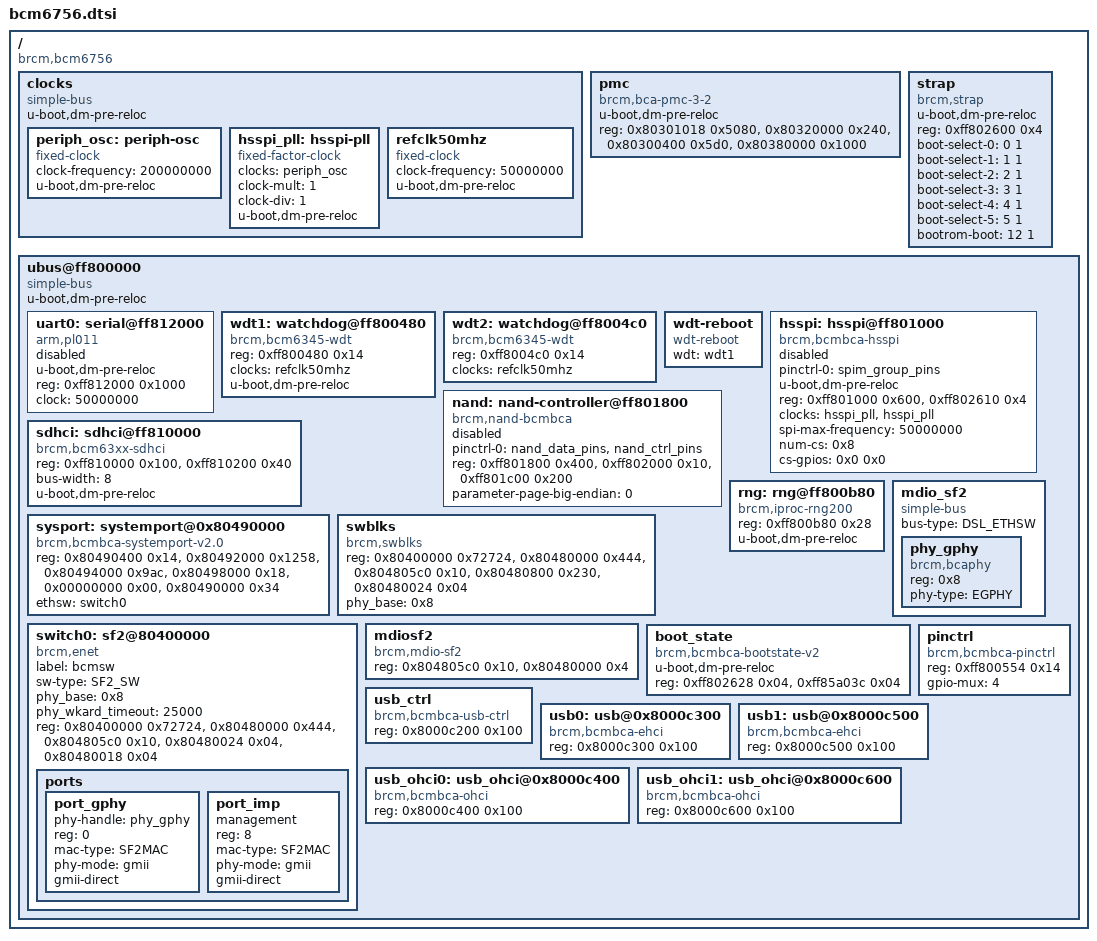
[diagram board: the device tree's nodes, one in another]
// SPDX-License-Identifier: GPL-2.0+
/*
 * Copyright 2021 Broadcom Ltd.
 */

#include "skeleton.dtsi"

/ {
	compatible = "brcm,bcm6756";
	#address-cells = <0x1>;
	#size-cells = <0x1>;

	clocks {
		compatible = "simple-bus";
		#address-cells = <1>;
		#size-cells = <1>;
		ranges;
		u-boot,dm-pre-reloc;

		periph_osc: periph-osc {
			compatible = "fixed-clock";
			#clock-cells = <0>;
			clock-frequency = <200000000>;
			u-boot,dm-pre-reloc;
		};

		hsspi_pll: hsspi-pll {
			compatible = "fixed-factor-clock";
			#clock-cells = <0>;
			clocks = <&periph_osc>;
			clock-mult = <1>;
			clock-div = <1>;
			u-boot,dm-pre-reloc;
		};

		refclk50mhz: refclk50mhz {
			compatible = "fixed-clock";
			#clock-cells = <0>;
			clock-frequency = <50000000>;
			u-boot,dm-pre-reloc;
		};
	};

	pmc {
		u-boot,dm-pre-reloc;
		compatible = "brcm,bca-pmc-3-2";
		reg-names = "pmc", "procmon", "maestro","dtcm"; 
 		reg = <0x80301018 0x5080>,
 		      <0x80320000 0x240>,
 		      <0x80300400 0x5d0>,
 		      <0x80380000 0x1000>;
	};

	strap: strap {
		u-boot,dm-pre-reloc;	
		compatible = "brcm,strap";
		reg = <0xff802600 0x4>;
		boot-select-0=<0 1>;
		boot-select-1=<1 1>;
		boot-select-2=<2 1>;
		boot-select-3=<3 1>;
		boot-select-4=<4 1>;
		boot-select-5=<5 1>;
		bootrom-boot=<12 1>;
	};

	ubus@ff800000 {
		compatible = "simple-bus";
		#address-cells = <0x1>;
		#size-cells = <0x1>;
		u-boot,dm-pre-reloc;

		uart0: serial@ff812000 {	
			u-boot,dm-pre-reloc;
			compatible = "arm,pl011", "arm,primecell";
			reg = <0xff812000 0x1000>;
			clock = <50000000>;
			status = "disabled";
		};

		wdt1: watchdog@ff800480 {
			compatible = "brcm,bcm6345-wdt";
			reg = <0xff800480 0x14>;
			clocks = <&refclk50mhz>;
			u-boot,dm-pre-reloc;
		};

		wdt2: watchdog@ff8004c0 {
			compatible = "brcm,bcm6345-wdt";
			reg = <0xff8004c0 0x14>;
			clocks = <&refclk50mhz>;
		};

		wdt-reboot {
			compatible = "wdt-reboot";
			wdt = <&wdt1>;
		};

		hsspi: hsspi@ff801000 {
			pinctrl-0 = <&spim_group_pins>;
			pinctrl-names = "default";
			#address-cells = <0x1>;
			#size-cells = <0x0>;
			u-boot,dm-pre-reloc;
			compatible = "brcm,bcmbca-hsspi";
			reg-names = "hsspi", "spim-ctrl";
			reg = <0xff801000 0x600>, <0xff802610 0x4>;
			clocks = <&hsspi_pll>, <&hsspi_pll>;
			clock-names = "hsspi", "pll";
			spi-max-frequency = <50000000>;
			num-cs = <0x8>;
			cs-gpios = <0x0 0x0>;
			status = "disabled";
		};

		nand: nand-controller@ff801800 {
			pinctrl-0 = <&nand_data_pins &nand_ctrl_pins>;
			pinctrl-names = "default";	
			compatible = "brcm,nand-bcmbca",
				     "brcm,brcmnand-v7.1",
				     "brcm,brcmnand";
			reg-names = "nand", "nand-int-base", "nand-cache";
			reg = <0xff801800 0x400>,
			      <0xff802000 0x10>,
			      <0xff801c00 0x200>;
			parameter-page-big-endian = <0>;
			status = "disabled";
		};

		sdhci: sdhci@ff810000 {
			compatible = "brcm,bcm63xx-sdhci",
			             "brcm,sdhci-brcmbca";
			reg-names = "sdhci-base", "sdhci-boot";
			reg = <0xff810000 0x100>,
			      <0xff810200 0x40>;
			bus-width = <8>;
			u-boot,dm-pre-reloc;
		};

		rng: rng@ff800b80 {
			compatible = "brcm,iproc-rng200";
			reg = <0xff800b80 0x28>;
			u-boot,dm-pre-reloc;
		};
		
		sysport: systemport@0x80490000 {
			compatible = "brcm,bcmbca-systemport-v2.0";
			reg-names = "systemport-rbuf-base", "systemport-rdma-base",
					"systemport-tdma-base",
					"systemport-gib-base",
					"systemport-umac-base",
					"systemport-topctrl-base";
			reg =		<0x80490400 0x14>,
					<0x80492000 0x1258>,
					<0x80494000 0x9ac>,
					<0x80498000 0x18>,
					<0x00000000 0x00>,  
					<0x80490000 0x34>;
			ethsw = <&switch0>;
		};

    	swblks {
    		compatible = "brcm,swblks";
    		reg-names =	"switchcore-base",
    				"switchreg-base",
    				"switchmdio-base",
    				"switchacb-base",
    				"sphy-ctrl";

    		reg	= <0x80400000 0x72724>,
    			<0x80480000 0x444>,
    			<0x804805c0 0x10>,
    			<0x80480800 0x230>,
    			<0x80480024 0x04>;
    		phy_base = <0x8>;
    	};

		mdio_sf2: mdio_sf2 {
			compatible = "simple-bus";
			bus-type = "DSL_ETHSW";

			#address-cells = <1>;
			#size-cells = <0>;

			phy_gphy:phy_gphy {
				compatible = "brcm,bcaphy";
				reg = <0x8>;
				phy-type = "EGPHY";
			};
		};

		switch0:sf2@80400000 {
			compatible = "brcm,enet", "brcm,bcmbca-sf2";
			label = "bcmsw";
			sw-type = "SF2_SW";

			phy_base = <0x8>;
			phy_wkard_timeout = <25000>;
			reg-names = "switchcore-base",
						"switchreg-base",
						"switchmdio-base",
						"sphy-ctrl",
						"phy-test-ctrl";

			reg = <0x80400000 0x72724>,
				<0x80480000 0x444>,
				<0x804805c0 0x10>,
				<0x80480024 0x04>,
				<0x80480018 0x04>;

			ports {
				#address-cells = <1>;
				#size-cells = <0>;

				port_gphy {
					phy-handle = <&phy_gphy>;
					reg = <0>;
					mac-type = "SF2MAC";
					phy-mode = "gmii";
					gmii-direct;
				};
				port_imp {
					management;
					reg = <8>;
					mac-type = "SF2MAC";
					phy-mode = "gmii";
					gmii-direct;
				};
			};		
		};

		mdiosf2 {
			compatible = "brcm,mdio-sf2";
			reg = <0x804805c0 0x10>,
				  <0x80480000 0x4>;
		};

		boot_state {
			u-boot,dm-pre-reloc;
			compatible = "brcm,bcmbca-bootstate-v2";
			reg-names = "reset_reason", "reset_status";
			reg = <0xff802628 0x04>,
				<0xff85a03c 0x04>;
		};

		pinctrl: pinctrl {
			compatible = "brcm,bcmbca-pinctrl";
			reg = <0xff800554 0x14>;
			gpio-mux = <4>;
		};

		usb_ctrl:usb_ctrl {
			compatible = "brcm,bcmbca-usb-ctrl";
			reg-names = "usb-ctrl";
			reg = <0x8000c200 0x100>;
			status = "okay";
		};

		usb0: usb@0x8000c300 {
			compatible = "brcm,bcmbca-ehci";
			reg-names = "usb-ehci";
			reg = <0x8000c300 0x100>;
		};

		usb1: usb@0x8000c500 {
			compatible = "brcm,bcmbca-ehci";
			reg-names = "usb-ehci";
			reg = <0x8000c500 0x100>;
		};

		usb_ohci0: usb_ohci@0x8000c400 {
			compatible = "brcm,bcmbca-ohci";
			reg-names = "usb-ohci";
			reg = <0x8000c400 0x100>;
		};

		usb_ohci1: usb_ohci@0x8000c600 {
			compatible = "brcm,bcmbca-ohci";
			reg-names = "usb-ohci";
			reg = <0x8000c600 0x100>;
		};
	};
};

#include "bcm6756-pinctrl.dtsi"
